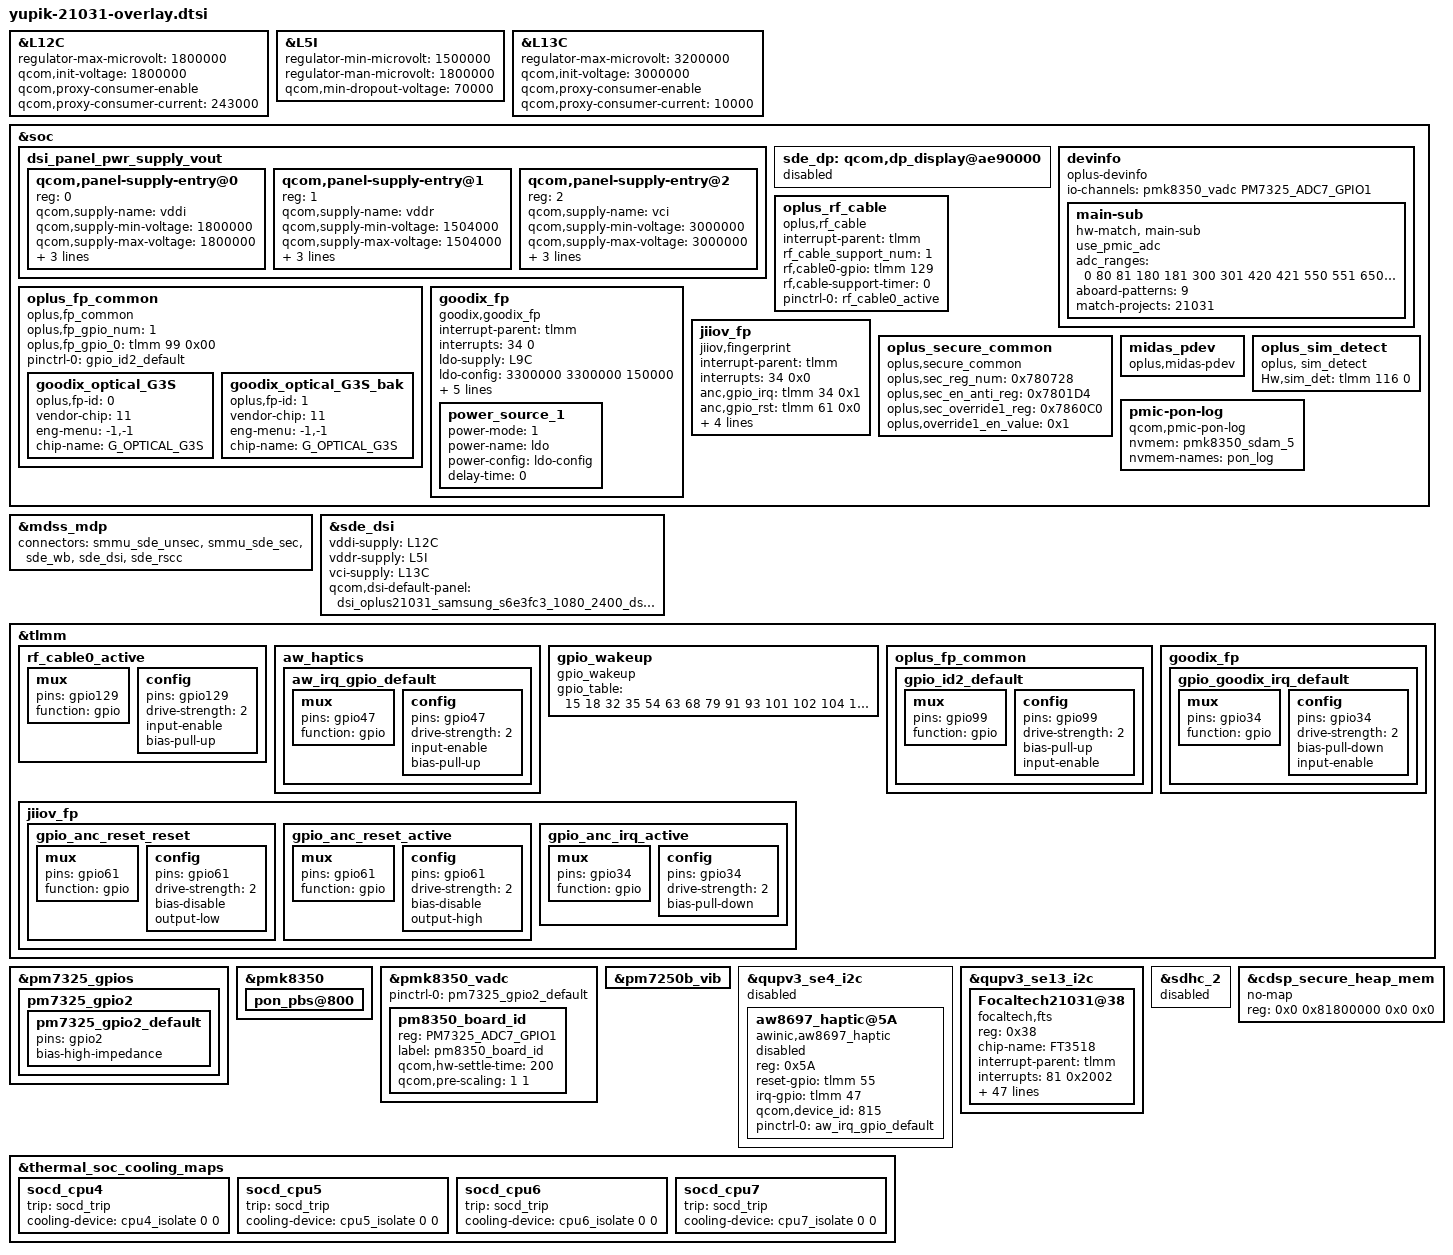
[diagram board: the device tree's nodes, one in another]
/*#ifdef OPLUS_FEATURE_SENSOR_DRIVER*/
#include "sensor/libai-sensor-21031.dtsi"
/*#endif*/

//#ifdef OPLUS_FEATURE_CHG_BASIC
#include "charge/libai_charge.dtsi"
//#endif

//#ifdef OPLUS_BUG_STABILITY
#include "dsi-panel-oplus21031-samsung-s6e3fc3-1080-2400-dsc-cmd.dtsi"
//VDDI
&L12C {
	regulator-max-microvolt = <1800000>;
	qcom,init-voltage = <1800000>;
	qcom,proxy-consumer-enable;
	qcom,proxy-consumer-current = <243000>;
};
//VDDR(VOUT)
&L5I {
	regulator-min-microvolt = <1500000>;
	regulator-man-microvolt = <1800000>;
	qcom,min-dropout-voltage = <70000>;
};
//VCI
&L13C {
	regulator-max-microvolt = <3200000>;
	qcom,init-voltage = <3000000>;
	qcom,proxy-consumer-enable;
	qcom,proxy-consumer-current = <10000>;
};
&soc {
	dsi_panel_pwr_supply_vout: dsi_panel_pwr_supply_vout {
		#address-cells = <1>;
		#size-cells = <0>;

		qcom,panel-supply-entry@0 {
			reg = <0>;
			qcom,supply-name = "vddi";
			qcom,supply-min-voltage = <1800000>;
			qcom,supply-max-voltage = <1800000>;
			qcom,supply-enable-load = <60700>;
			qcom,supply-disable-load = <80>;
			qcom,supply-post-on-sleep = <0>;
		};
		qcom,panel-supply-entry@1 {
			reg = <1>;
			qcom,supply-name = "vddr";
			qcom,supply-min-voltage = <1504000>;
			qcom,supply-max-voltage = <1504000>;
			qcom,supply-enable-load = <60700>;
			qcom,supply-disable-load = <80>;
			qcom,supply-post-on-sleep = <0>;
		};
		qcom,panel-supply-entry@2 {
			reg = <2>;
			qcom,supply-name = "vci";
			qcom,supply-min-voltage = <3000000>;
			qcom,supply-max-voltage = <3000000>;
			qcom,supply-enable-load = <10000>;
			qcom,supply-disable-load = <0>;
			qcom,supply-post-on-sleep = <0>;
		};
	};
};

&soc {
	sde_dp: qcom,dp_display@ae90000 {
		status = "disabled";
	};
};
&mdss_mdp {
	connectors = <&smmu_sde_unsec &smmu_sde_sec &sde_wb &sde_dsi &sde_rscc>;
};

&sde_dsi {
	/delete-property/ lab-supply;
	/delete-property/ ibb-supply;
	vddi-supply = <&L12C>;	//PM7350C LDO12
	vddr-supply = <&L5I>;	//PM8008 LDO5
	vci-supply = <&L13C>;	//PM7350C LDC13
	qcom,dsi-default-panel = <&dsi_oplus21031_samsung_s6e3fc3_1080_2400_dsc_cmd>;
};
//#endif /* OPLUS_BUG_STABILITY */

&tlmm {

	rf_cable0_active: rf_cable0_active {
		mux {
			pins = "gpio129";
			function = "gpio";
		};
		config {
			pins = "gpio129";
			drive-strength = <2>;
			input-enable;
			bias-pull-up;
		};
	};

};



&pm7325_gpios {
	pm7325_gpio2 {
		pm7325_gpio2_default: pm7325_gpio2_default {
			pins = "gpio2";
			bias-high-impedance;
		};
	};
};

&pmk8350 {
        pon_pbs@800 {
                status = "ok";
        };
};

&pmk8350_vadc {
	pinctrl-names = "default";

	pinctrl-0 = <&pm7325_gpio2_default>;

	pm8350_board_id {
		reg = <PM7325_ADC7_GPIO1>;
		label = "pm8350_board_id";
		//qcom,ratiometric;
		qcom,hw-settle-time = <200>;
		qcom,pre-scaling = <1 1>;
	};
};



&soc {
	devinfo {
		compatible = "oplus-devinfo";

		//pinctrl-names = "active", "sleep";
		//pinctrl-0 = <&hw_id_active>;
		//pinctrl-1 = <&hw_id_sleep>;

		io-channels= <&pmk8350_vadc PM7325_ADC7_GPIO1>;
		io-channel-names= "vph_pwr_voltage_sub";

		main-sub {
			compatible = "hw-match, main-sub";
			use_pmic_adc;
			adc_ranges = <0 80
					81 180
					181 300
					301 420
					421 550
					551 650
					651 760
					761 850
					851 950
					951 1050
					1051 1150
					1151 1300>;
			aboard-patterns = <9>;

			/*main board*/
			match-projects = <21031>;

			/*rf type*/
			//rf_match_support;
			//rf-patterns = <0 0>;
		};
	};

	oplus_rf_cable {
		compatible = "oplus,rf_cable";
		interrupt-parent = <&tlmm>;
		rf_cable_support_num = <1>;
		rf,cable0-gpio = <&tlmm 129 0>;
		rf,cable-support-timer = <0>;
		pinctrl-names = "rf_cable_active";
		pinctrl-0 = <&rf_cable0_active>;
	};
};

&pm7250b_vib {
	status = "ok";
};

&tlmm {
	aw_haptics: aw_haptics {
		aw_irq_gpio_default: aw_irq_gpio_default {
			mux {
				pins = "gpio47";
				function = "gpio";
			};

			config {
				pins = "gpio47";
				drive-strength = <2>;
				input-enable;
				bias-pull-up; /*PULL UP*/
				//bias-disable;
			};
		};
	};
};

&qupv3_se4_i2c  {
	//status = "ok";
	/* AWINIC AW8697 Haptic */
	aw8697_haptic@5A {
		compatible = "awinic,aw8697_haptic";
		reg = <0x5A>;
		reset-gpio = <&tlmm 55 0>;
		irq-gpio = <&tlmm 47 0>;
		status = "disabled";
		qcom,device_id = <815>;//19066

		pinctrl-names = "default";
		pinctrl-0 = <&aw_irq_gpio_default>;
	};
	/* AWINIC AW8697 Haptic End */
};
//#endif

&qupv3_se4_i2c {
	status = "disable";
};
&qupv3_se13_i2c {
	#address-cells = <1>;
	#size-cells = <0>;

	status = "ok";

	Focaltech21031@38 {
		compatible = "focaltech,fts";
		reg = <0x38>;
		chip-name = "FT3518";

		/* Interrupt && Irq-gpio */
		interrupt-parent = <&tlmm>;
		interrupts = <81 0x2002>;

		/* Power Config */
		vdd_2v8-supply = <&L3C>;
		vcc_1v8-supply = <&L12C>;
		vdd_2v8_volt = <3008000>;

		/* Interrupt && Irq-gpio */
                /* Other HW Resource */
		irq-gpio = <&tlmm 81 0x2002>;
		reset-gpio = <&tlmm 105 0x1>;
		/*pinctrl-names = "default";*/
		/*pinctrl-0 = <&ts_int_active &ts_reset_active>;*/

		pinctrl-names = "pmx_ts_active","pmx_ts_suspend",
					"pmx_ts_release";

		pinctrl-0 = <&ts_active>;
		pinctrl-1 = <&ts_int_suspend &ts_reset_suspend>;
		pinctrl-2 = <&ts_release>;

		panel = <&dsi_oplus21031_samsung_s6e3fc3_1080_2400_dsc_cmd>;

		touchpanel,max-num-support = <10>;
		touchpanel,tx-rx-num = <16 34>;
		touchpanel,panel-coords = <4320 9600>;
		touchpanel,display-coords = <1080 2400>;
		touchpanel,touchmajor-limit = <0 216>;
		touchpanel,smooth-level = <255 2 15 25 45 60>;
		touchpanel,smooth-level-charging = <255 15 20 25 45 60>;
		touchpanel,sensitive-level = <255 20 17 14 10 5>;
		touchpanel,high-frame-rate-time = <20>;
		project_id = <21031>;
		panel_type = <8>;
		tp_type = <8>;
		firmware_name = "0xAA29000";
		platform_support_project = <21031>;
		platform_support_project_dir = <21031>;
		platform_support_project_commandline = "default_commandline";
		/* SW Support Feature Control */
		black_gesture_support;
		black_gesture_indep_support;
		sportify_aod_gesture_support;
		fw_edge_limit_support;
		pressure_report_support;
		charger_pump_support;
		game_switch_support;
		smart_gesture_support;
		fw_update_app_support;
		fingerprint_underscreen_support;
		headset_pump_support;
		//esd_handle_support;
		new_set_irq_wake_support;
		irq_need_dev_resume_ok;
		health_monitor_support;
		high_resolution_support;
		lcd_tp_refresh_support;
		exception_upload_support;
		/*
		*Virtual Key Config:
		*1:touchpanel,button-type: <virtualkey_type  supportted_button-map>
		*virtualkey_type:
		*Type 1: using board_properties
		*Type 2: using same IC (button zone&& touch zone are seprate)
		*Type 3: using diffrent IC (button zone&& touch zone are seprate)
		*Type 4: No need of virtual key process
		*supportted_button-map:select|menu|home|back
		*
		*2:touchpanel,button-map
		*type (X1,Y1)(X2,Y2)(X3,Y3)(Width_X,Hight_Y)--Only when button-type is 0
		*/
		touchpanel,button-type = <4>;
		touchpanel.button-TRx = <0 0>;
	};
};
//Baihang.Wang 2021/08/26 add for disable wake-up function of NC-GPIO
&tlmm {
	gpio_wakeup: gpio_wakeup {
		compatible = "gpio_wakeup";
		gpio_table = <15 18 32 35 54 63 68 79 91 93 101 102 104 130 136 155 156 157 158 174 82 56 59>;
	};
};

//#ifdef OPLUS_FEATURE_FINGERPRINT
&sdhc_2 {
	status = "disabled";
};

&tlmm {

	oplus_fp_common{
		gpio_id2_default: gpio_id2_default {
			mux {
				pins = "gpio99";
				function = "gpio";
			};
			config {
				pins = "gpio99";
				drive-strength = <2>;
				bias-pull-up;
				input-enable;
			};
		};
	};

	goodix_fp{
		gpio_goodix_irq_default: gpio_goodix_irq_default {
			mux {
				pins = "gpio34";
				function = "gpio";
			};
			config {
				pins = "gpio34";
				drive-strength = <2>;
				bias-pull-down;
				input-enable;
			};
		};
	};
	jiiov_fp{
		gpio_anc_reset_reset: gpio_anc_reset_reset {
			mux {
				pins = "gpio61";
				function = "gpio";
			};
			config {
				pins = "gpio61";
				drive-strength = <2>;
				bias-disable;
				output-low;
			};
		};
		gpio_anc_reset_active: gpio_anc_reset_active {
			mux {
				pins = "gpio61";
				function = "gpio";
			};
			config {
				pins = "gpio61";
				drive-strength = <2>;
				bias-disable;
				output-high;
			};
		};
		gpio_anc_irq_active: gpio_anc_irq_active {
			mux {
				pins = "gpio34";
				function = "gpio";
			};
			config {
				pins = "gpio34";
				drive-strength = <2>;
				bias-pull-down;
			};
		};
	};
};

/* delete low battery policy for performance */
&thermal_soc_cooling_maps {
	socd_cpu4 {
		trip = <&socd_trip>;
		cooling-device = <&cpu4_isolate 0 0>;
	};

	socd_cpu5 {
		trip = <&socd_trip>;
		cooling-device = <&cpu5_isolate 0 0>;
	};

	socd_cpu6 {
		trip = <&socd_trip>;
		cooling-device = <&cpu6_isolate 0 0>;
	};

	socd_cpu7 {
		trip = <&socd_trip>;
		cooling-device = <&cpu7_isolate 0 0>;
	};
};

&soc {
	oplus_fp_common {
		compatible = "oplus,fp_common";
		oplus,fp_gpio_num = <1>;
		oplus,fp_gpio_0 = <&tlmm 99 0x00>;
		pinctrl-names = "default";
		pinctrl-0 = <&gpio_id2_default>;
		goodix_optical_G3S {
			oplus,fp-id = <0>; /* fp id mapping table */
			vendor-chip = <11>; /* please refer to the struct fp_vendor_t in oplus_fp_commmon.n */
			eng-menu = "-1,-1"; /* represents SNR, inclination test item in engineer menu, and 0/1 means off/on */
			chip-name = "G_OPTICAL_G3S";  /* /proc/fp_id, will be displayed in engineer menu  */
		};
		goodix_optical_G3S_bak {
			oplus,fp-id = <1>; /* fp id mapping table */
			vendor-chip = <11>; /* please refer to the struct fp_vendor_t in oplus_fp_commmon.n */
			eng-menu = "-1,-1"; /* represents SNR, inclination test item in engineer menu, and 0/1 means off/on */
			chip-name = "G_OPTICAL_G3S";  /* /proc/fp_id, will be displayed in engineer menu  */
		};
	};

	goodix_fp {
		status = "ok";
		compatible = "goodix,goodix_fp";
		interrupt-parent = <&tlmm>;
		interrupts = <34 0>;
		ldo-supply = <&L9C>;
		ldo-config = <3300000 3300000 150000>;
		goodix,gpio_irq = <&tlmm 34 0x1>;
		goodix,gpio_reset = <&tlmm 61 0x0>;
		pinctrl-names = "default";
		pinctrl-0 = <&gpio_goodix_irq_default>;
		notify_tpinfo_flag = <1>;
		power-num = <1>;
		power_source_1 {
			power-mode = <1>;
			power-name = "ldo";
			power-config = "ldo-config";
			delay-time = <0>;
		};
	};

	jiiov_fp {
		status = "ok";
		compatible = "jiiov,fingerprint";
		interrupt-parent = <&tlmm>;
		interrupts = <34 0x0>;
		anc,gpio_irq = <&tlmm 34 0x1>;
		anc,gpio_rst = <&tlmm 61 0x0>;
		ldo-supply = <&L9C>;
		pinctrl-names = "anc_reset_reset", "anc_reset_active", "anc_irq_active";
		pinctrl-0 = <&gpio_anc_reset_reset>;
		pinctrl-1 = <&gpio_anc_reset_active>;
		pinctrl-2 = <&gpio_anc_irq_active>;
	};

	oplus_secure_common {
		compatible = "oplus,secure_common";
		oplus,sec_reg_num = <0x780728>;
		oplus,sec_en_anti_reg = <0x7801D4>;
		oplus,sec_override1_reg = <0x7860C0>;
		oplus,override1_en_value = <0x1>;
	};

	midas_pdev {
		compatible = "oplus,midas-pdev";
	};

    //#ifdef OPLUS_FEATURE_TP_BASIC
	oplus_sim_detect {
		compatible = "oplus, sim_detect";
		Hw,sim_det = <&tlmm 116 0>;
	};
    //#endif /* OPLUS_FEATURE_TP_BASIC */

};

&soc {
	pmic-pon-log {
		compatible = "qcom,pmic-pon-log";
		nvmem = <&pmk8350_sdam_5>;
		nvmem-names = "pon_log";
	};
};

//#ifdef OPLUS_FEATURE_FINGERPRINT
&cdsp_secure_heap_mem {
	no-map;
	reg = <0x0 0x81800000 0x0 0x0>;
};
//#endif /*OPLUS_FEATURE_FINGERPRINT*/
